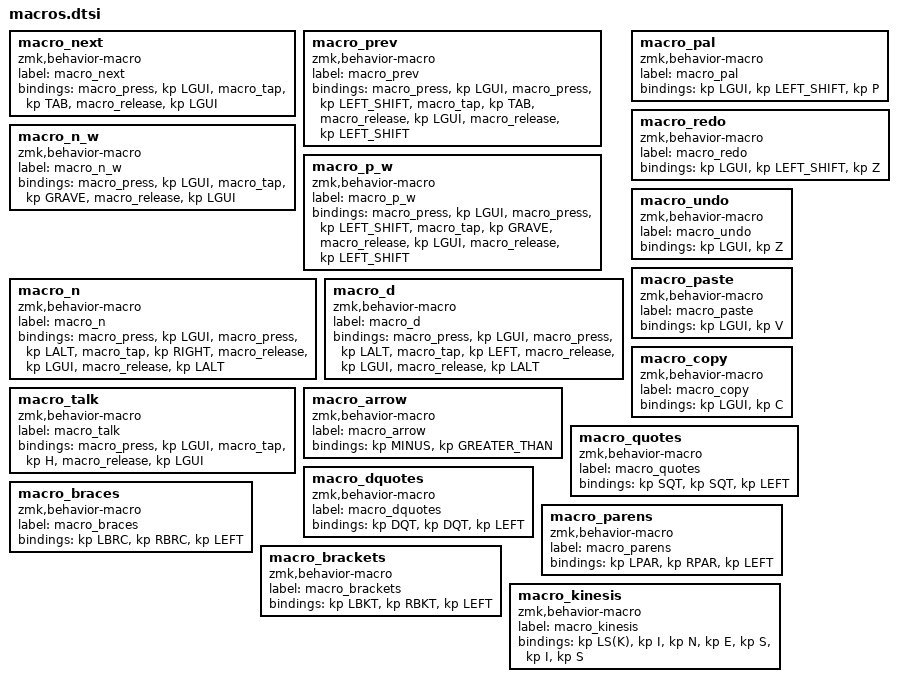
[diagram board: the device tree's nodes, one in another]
macro_next: macro_next{
compatible = "zmk,behavior-macro";
label = "macro_next";
#binding-cells = <0>;
bindings = <&macro_press &kp LGUI>, <&macro_tap &kp TAB>, <&macro_release &kp LGUI>; 
};
macro_prev: macro_prev{
    compatible = "zmk,behavior-macro";
    label = "macro_prev";
    #binding-cells = <0>;
    bindings = <&macro_press &kp LGUI>, <&macro_press &kp LEFT_SHIFT>, <&macro_tap &kp TAB>, <&macro_release &kp LGUI>, <&macro_release &kp LEFT_SHIFT>; 
};
macro_n_w: macro_n_w {
compatible = "zmk,behavior-macro";
label = "macro_n_w";
#binding-cells = <0>;
bindings = <&macro_press &kp LGUI>, <&macro_tap &kp GRAVE>, <&macro_release &kp LGUI>; 
};
macro_p_w: macro_p_w {
compatible = "zmk,behavior-macro";
label = "macro_p_w";
#binding-cells = <0>;
bindings = <&macro_press &kp LGUI>, <&macro_press &kp LEFT_SHIFT>, <&macro_tap &kp GRAVE>, <&macro_release &kp LGUI>, <&macro_release &kp LEFT_SHIFT>; 
};
macro_n: macro_n{
compatible = "zmk,behavior-macro";
label = "macro_n";
#binding-cells = <0>;
bindings = <&macro_press &kp LGUI>, <&macro_press &kp LALT>, <&macro_tap &kp RIGHT>, <&macro_release &kp LGUI>, <&macro_release &kp LALT>; 
};
macro_d: macro_d{
compatible = "zmk,behavior-macro";
label = "macro_d";
#binding-cells = <0>;
bindings = <&macro_press &kp LGUI>, <&macro_press &kp LALT>, <&macro_tap &kp LEFT>, <&macro_release &kp LGUI>, <&macro_release &kp LALT>; 
};
macro_pal: macro_pal{
compatible = "zmk,behavior-macro";
label = "macro_pal";
#binding-cells = <0>;
bindings = <&kp LGUI>, <&kp LEFT_SHIFT>, <&kp P>;
};
macro_talk: macro_talk{
compatible = "zmk,behavior-macro";
label = "macro_talk";
#binding-cells = <0>;
bindings = <&macro_press &kp LGUI>, <&macro_tap &kp H>, <&macro_release &kp LGUI>;
};
macro_redo: macro_redo{
compatible = "zmk,behavior-macro";
label = "macro_redo";
#binding-cells = <0>;
bindings = <&kp LGUI>, <&kp LEFT_SHIFT>, <&kp Z>;
};
macro_undo: macro_undo{
compatible = "zmk,behavior-macro";
label = "macro_undo";
#binding-cells = <0>;
bindings = <&kp LGUI>, <&kp Z>;
};
macro_paste: macro_paste{
compatible = "zmk,behavior-macro";
label = "macro_paste";
#binding-cells = <0>;
bindings = <&kp LGUI>, <&kp V>;
};
macro_copy: macro_copy{
compatible = "zmk,behavior-macro";
label = "macro_copy";
#binding-cells = <0>;
bindings = <&kp LGUI>, <&kp C>;
};
macro_arrow: macro_arrow{
compatible = "zmk,behavior-macro";
label = "macro_arrow";
#binding-cells = <0>;
bindings = <&kp MINUS>, <&kp GREATER_THAN>;
};
macro_quotes: macro_quotes{
compatible = "zmk,behavior-macro";
label = "macro_quotes";
#binding-cells = <0>;
bindings = <&kp SQT>, <&kp SQT>, <&kp LEFT>;
};
macro_dquotes: macro_dquotes{
compatible = "zmk,behavior-macro";
label = "macro_dquotes";
#binding-cells = <0>;
bindings = <&kp DQT>, <&kp DQT>, <&kp LEFT>;
};
macro_braces: macro_braces{
compatible = "zmk,behavior-macro";
label = "macro_braces";
#binding-cells = <0>;
bindings = <&kp LBRC>, <&kp RBRC>, <&kp LEFT>;
};
macro_parens: macro_parens{
compatible = "zmk,behavior-macro";
label = "macro_parens";
#binding-cells = <0>;
bindings = <&kp LPAR>, <&kp RPAR>, <&kp LEFT>;
};
macro_brackets: macro_brackets{
compatible = "zmk,behavior-macro";
label = "macro_brackets";
#binding-cells = <0>;
bindings = <&kp LBKT>, <&kp RBKT>, <&kp LEFT>;
};
macro_kinesis: macro_kinesis{
compatible = "zmk,behavior-macro";
label = "macro_kinesis";
#binding-cells = <0>;
bindings = <&kp LS(K)>, <&kp I>, <&kp N>, <&kp E>, <&kp S>, <&kp I>, <&kp S>;
};



